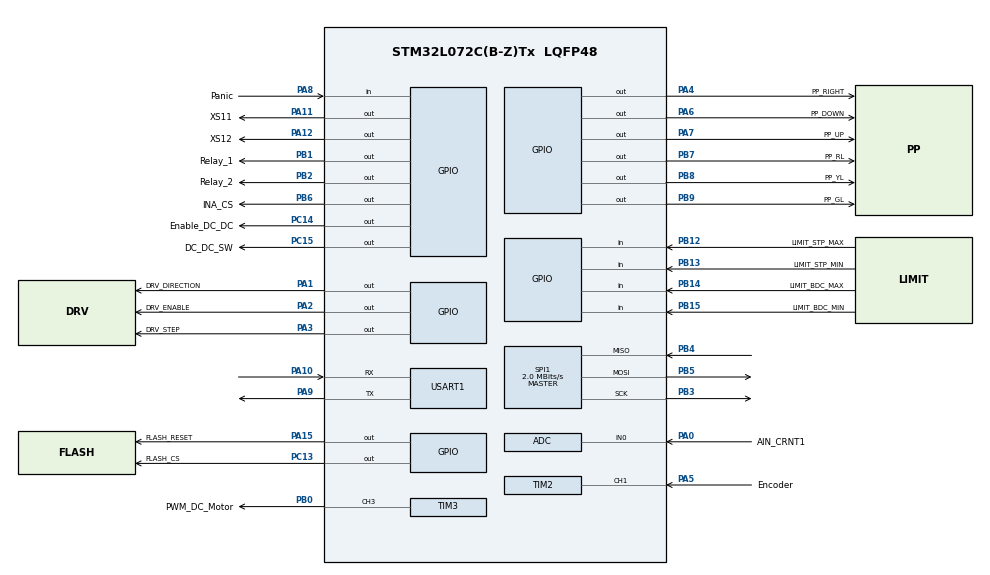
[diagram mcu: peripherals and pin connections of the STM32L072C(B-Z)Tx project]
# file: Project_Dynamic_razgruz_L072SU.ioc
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IWDG.Prescaler=IWDG_PRESCALER_128
IWDG.Reload=289
IWDG.Window=289
Mcu.Family=STM32L0
Mcu.Name=STM32L072C(B-Z)Tx
Mcu.Package=LQFP48
Mcu.UserConstants=FREQUENCY_STEP,31
NVIC.SPI1_IRQn=true\:2\:0\:true\:false\:true\:true\:true
NVIC.TIM21_IRQn=true\:1\:0\:true\:false\:true\:true\:true
NVIC.TIM22_IRQn=true\:0\:0\:true\:false\:true\:true\:true
NVIC.TIM2_IRQn=true\:2\:0\:true\:false\:true\:true\:true
NVIC.TIM6_DAC_IRQn=true\:1\:0\:true\:false\:true\:true\:true
NVIC.USART1_IRQn=true\:1\:0\:true\:false\:true\:true\:true
PA0.GPIO_Label=AIN_CRNT1
PA0.Mode=IN0
PA0.Signal=ADC_IN0
PA1.GPIO_Label=DRV_DIRECTION
PA1.GPIO_Speed=GPIO_SPEED_FREQ_VERY_HIGH
PA1.Signal=GPIO_Output
PA10.Mode=Asynchronous
PA10.Signal=USART1_RX
PA11.GPIO_Label=XS11
PA11.Signal=GPIO_Output
PA12.GPIO_Label=XS12
PA12.Signal=GPIO_Output
PA13.Mode=Serial_Wire
PA13.Signal=SYS_SWDIO
PA14.Mode=Serial_Wire
PA14.Signal=SYS_SWCLK
PA15.GPIO_Label=FLASH_RESET
PA15.Signal=GPIO_Output
PA2.GPIO_Label=DRV_ENABLE
PA2.GPIO_Speed=GPIO_SPEED_FREQ_VERY_HIGH
PA2.Signal=GPIO_Output
PA3.GPIO_Label=DRV_STEP
PA3.GPIO_Speed=GPIO_SPEED_FREQ_VERY_HIGH
PA3.Signal=GPIO_Output
PA4.GPIO_Label=PP_RIGHT
PA4.Signal=GPIO_Output
PA5.GPIO_Label=Encoder
PA5.Signal=S_TIM2_CH1
PA6.GPIO_Label=PP_DOWN
PA6.Signal=GPIO_Output
PA7.GPIO_Label=PP_UP
PA7.Signal=GPIO_Output
PA8.GPIO_Label=Panic
PA8.Signal=GPIO_Input
PA9.Mode=Asynchronous
PA9.Signal=USART1_TX
PB0.GPIO_Label=PWM_DC_Motor
PB0.Signal=S_TIM3_CH3
PB1.GPIO_Label=Relay_1
PB1.Signal=GPIO_Output
PB12.GPIO_Label=LIMIT_STP_MAX
PB12.GPIO_PuPd=GPIO_PULLUP
PB12.Signal=GPIO_Input
PB13.GPIO_Label=LIMIT_STP_MIN
PB13.GPIO_PuPd=GPIO_PULLUP
PB13.Signal=GPIO_Input
PB14.GPIO_Label=LIMIT_BDC_MAX
PB14.GPIO_PuPd=GPIO_PULLUP
PB14.Signal=GPIO_Input
PB15.GPIO_Label=LIMIT_BDC_MIN
PB15.GPIO_PuPd=GPIO_PULLUP
PB15.Signal=GPIO_Input
PB2.GPIO_Label=Relay_2
PB2.Signal=GPIO_Output
PB3.Mode=Full_Duplex_Master
PB3.Signal=SPI1_SCK
PB4.Mode=Full_Duplex_Master
PB4.Signal=SPI1_MISO
PB5.Mode=Full_Duplex_Master
PB5.Signal=SPI1_MOSI
PB6.GPIO_FM6=__NULL
PB6.GPIO_Label=INA_CS
PB6.Signal=GPIO_Output
PB7.GPIO_Label=PP_RL
PB7.Signal=GPIO_Output
PB8.GPIO_Label=PP_YL
PB8.Signal=GPIO_Output
PB9.GPIO_Label=PP_GL
PB9.Signal=GPIO_Output
PC13.GPIO_Label=FLASH_CS
PC13.Signal=GPIO_Output
PC14-OSC32_IN.GPIO_Label=Enable_DC_DC
PC14-OSC32_IN.Signal=GPIO_Output
PC15-OSC32_OUT.GPIO_Label=DC_DC_SW
PC15-OSC32_OUT.Signal=GPIO_Output
PH0-OSC_IN.Mode=HSE-External-Oscillator
PH0-OSC_IN.Signal=RCC_OSC_IN
PH1-OSC_OUT.Mode=HSE-External-Oscillator
PH1-OSC_OUT.Signal=RCC_OSC_OUT
ProjectManager.HeapSize=0x200
ProjectManager.StackSize=0x400
ProjectManager.TargetToolchain=MDK-ARM V5.27
RCC.AHBFreq_Value=32000000
RCC.APB1Freq_Value=32000000
RCC.APB1TimFreq_Value=32000000
RCC.APB2Freq_Value=32000000
RCC.APB2TimFreq_Value=32000000
RCC.HCLKFreq_Value=32000000
RCC.HSE_VALUE=8000000
RCC.HSI16_VALUE=16000000
RCC.HSI48_VALUE=48000000
RCC.HSI_VALUE=16000000
RCC.LSE_VALUE=32768
RCC.MSI_VALUE=2097000
RCC.PLLDIV=RCC_PLLDIV_3
RCC.PLLMUL=RCC_PLLMUL_12
RCC.PLLSourceVirtual=RCC_PLLSOURCE_HSE
RCC.SYSCLKFreq_VALUE=32000000
RCC.SYSCLKSource=RCC_SYSCLKSOURCE_PLLCLK
RCC.Usart1ClockSelection=RCC_USART1CLKSOURCE_HSI
RCC.VCOOutputFreq_Value=96000000
SH.S_TIM2_CH1.0=TIM2_CH1,TriggerSource_TI1FP1
SH.S_TIM2_CH1.1=TIM2_CH1,Input_Capture1_from_TI1
SH.S_TIM2_CH1.2=TIM2_CH1
SH.S_TIM3_CH3.0=TIM3_CH3,PWM Generation3 CH3
SPI1.BaudRatePrescaler=SPI_BAUDRATEPRESCALER_16
SPI1.CLKPhase=SPI_PHASE_2EDGE
SPI1.CalculateBaudRate=2.0 MBits/s
SPI1.DataSize=SPI_DATASIZE_8BIT
SPI1.Direction=SPI_DIRECTION_2LINES
SPI1.Mode=SPI_MODE_MASTER
SPI1.VirtualType=VM_MASTER
TIM2.AutoReloadPreload=TIM_AUTORELOAD_PRELOAD_DISABLE
TIM2.Channel-Input_Capture1_from_TI1=TIM_CHANNEL_1
TIM2.Channel-Input_Capture2_from_TI1_63=TIM_CHANNEL_2
TIM2.ICPolarity_CH2=TIM_INPUTCHANNELPOLARITY_FALLING
TIM2.Period=0xFFFF
TIM2.Prescaler=0xC7F
TIM21.AutoReloadPreload=TIM_AUTORELOAD_PRELOAD_ENABLE
TIM21.Period=10
TIM21.Prescaler=FREQUENCY_STEP
TIM22.AutoReloadPreload=TIM_AUTORELOAD_PRELOAD_ENABLE
TIM22.Period=10
TIM22.Prescaler=FREQUENCY_STEP
TIM3.AutoReloadPreload=TIM_AUTORELOAD_PRELOAD_DISABLE
TIM3.Channel-PWM\ Generation3\ CH3=TIM_CHANNEL_3
TIM3.OCFastMode_PWM-PWM\ Generation3\ CH3=TIM_OCFAST_DISABLE
TIM3.OCPolarity_3=TIM_OCPOLARITY_LOW
TIM3.Period=0x07CF
TIM3.Prescaler=3
TIM6.AutoReloadPreload=TIM_AUTORELOAD_PRELOAD_ENABLE
TIM6.Period=8438
TIM6.Prescaler=31999
USART1.DMADisableonRxErrorParam=ADVFEATURE_DMA_DISABLEONRXERROR
USART1.OneBitSampling=UART_ONE_BIT_SAMPLE_DISABLE
USART1.OverSampling=UART_OVERSAMPLING_16
USART1.OverrunDisableParam=ADVFEATURE_OVERRUN_DISABLE
USART1.VirtualMode-Asynchronous=VM_ASYNC
VP_IWDG_VS_IWDG.Mode=IWDG_Activate
VP_SYS_V_PVD_IN.Mode=Mode_PVD_Int
VP_TIM21_VS_ClockSourceINT.Mode=Internal
VP_TIM22_VS_ClockSourceINT.Mode=Internal
VP_TIM2_VS_ClockSourceINT.Mode=Internal
VP_TIM2_VS_ControllerModeReset.Mode=Reset Mode
VP_TIM2_VS_indirect_ch1.Mode=Input_Capture2_from_TI1_63
VP_TIM3_VS_ClockSourceINT.Mode=Internal
VP_TIM6_VS_ClockSourceINT.Mode=Enable_Timer
board=custom

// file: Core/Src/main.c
/* USER CODE BEGIN Header */
/**
  ******************************************************************************
  * @file           : main.c
  * @brief          : Main program body
  ******************************************************************************
  * @attention
  *
  * <h2><center>&copy; Copyright (c) 2021 STMicroelectronics.
  * All rights reserved.</center></h2>
  *
  * This software component is licensed by ST under BSD 3-Clause license,
  * the "License"; You may not use this file except in compliance with the
  * License. You may obtain a copy of the License at:
  *                        opensource.org/licenses/BSD-3-Clause
  *
  ******************************************************************************
  */
/* USER CODE END Header */
#include "main.h"
#include "adc.h"
#include "iwdg.h"
#include "spi.h"
#include "tim.h"
#include "usart.h"
#include "gpio.h"

void SystemClock_Config(void);

int main(void)
{

  /* MCU Configuration--------------------------------------------------------*/

  /* Reset of all peripherals, Initializes the Flash interface and the Systick. */
  HAL_Init();

  /* Configure the system clock */
  SystemClock_Config();

  /* Initialize all configured peripherals */
  MX_GPIO_Init();
  MX_TIM2_Init();
  MX_TIM3_Init();
  MX_TIM6_Init();
  MX_TIM21_Init();
  MX_TIM22_Init();
  MX_USART1_UART_Init();
  MX_ADC_Init();
  MX_SPI1_Init();
  MX_IWDG_Init();
  /* USER CODE BEGIN 2 */

	StartUpConfig();

  /* USER CODE END 2 */

  /* Infinite loop */
  /* USER CODE BEGIN WHILE */

  while (1)
  {
    LL_GPIO_TogglePin(XS12_GPIO_Port, XS12_Pin);

    SwitchControl();
		ButtonFlagControl();
		RingBuffer_flag = RingBuffer_tryread();
    /* USER CODE END WHILE */

    /* USER CODE BEGIN 3 */
    LL_IWDG_ReloadCounter(IWDG);
	}
  /* USER CODE END 3 */
}

void SystemClock_Config(void)
{
  LL_FLASH_SetLatency(LL_FLASH_LATENCY_1);
  while(LL_FLASH_GetLatency()!= LL_FLASH_LATENCY_1)
  {
  }
  LL_PWR_SetRegulVoltageScaling(LL_PWR_REGU_VOLTAGE_SCALE1);
  LL_RCC_HSE_Enable();

   /* Wait till HSE is ready */
  while(LL_RCC_HSE_IsReady() != 1)
  {

  }
  LL_RCC_HSI_Enable();

   /* Wait till HSI is ready */
  while(LL_RCC_HSI_IsReady() != 1)
  {

  }
  LL_RCC_HSI_SetCalibTrimming(16);
  LL_RCC_LSI_Enable();

   /* Wait till LSI is ready */
  while(LL_RCC_LSI_IsReady() != 1)
  {

  }
  LL_RCC_PLL_ConfigDomain_SYS(LL_RCC_PLLSOURCE_HSE, LL_RCC_PLL_MUL_12, LL_RCC_PLL_DIV_3);
  LL_RCC_PLL_Enable();

   /* Wait till PLL is ready */
  while(LL_RCC_PLL_IsReady() != 1)
  {

  }
  LL_RCC_SetAHBPrescaler(LL_RCC_SYSCLK_DIV_1);
  LL_RCC_SetAPB1Prescaler(LL_RCC_APB1_DIV_1);
  LL_RCC_SetAPB2Prescaler(LL_RCC_APB2_DIV_1);
  LL_RCC_SetSysClkSource(LL_RCC_SYS_CLKSOURCE_PLL);

   /* Wait till System clock is ready */
  while(LL_RCC_GetSysClkSource() != LL_RCC_SYS_CLKSOURCE_STATUS_PLL)
  {

  }
  LL_SetSystemCoreClock(32000000);

   /* Update the time base */
  if (HAL_InitTick (TICK_INT_PRIORITY) != HAL_OK)
  {
    Error_Handler();
  }
  LL_RCC_SetUSARTClockSource(LL_RCC_USART1_CLKSOURCE_HSI);
}

void Error_Handler(void)
{
}
